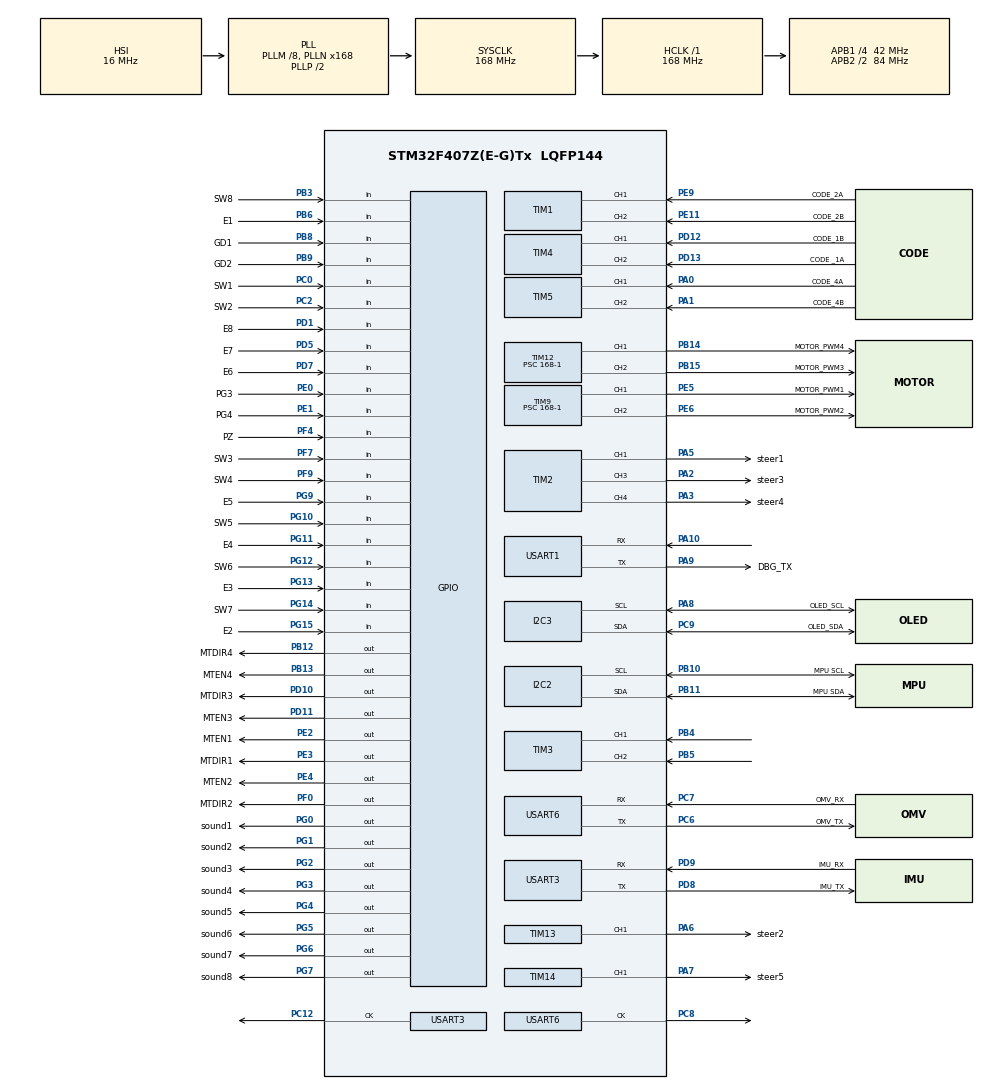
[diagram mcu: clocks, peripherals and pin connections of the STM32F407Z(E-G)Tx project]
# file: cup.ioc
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Mcu.Family=STM32F4
Mcu.Name=STM32F407Z(E-G)Tx
Mcu.Package=LQFP144
NVIC.PriorityGroup=NVIC_PRIORITYGROUP_4
NVIC.USART3_IRQn=true\:0\:0\:false\:false\:true\:true\:true\:true
PA0-WKUP.GPIO_Label=CODE_4A
PA0-WKUP.Signal=S_TIM5_CH1
PA1.GPIO_Label=CODE_4B
PA1.Signal=S_TIM5_CH2
PA10.Mode=Asynchronous
PA10.Signal=USART1_RX
PA13.Mode=Serial_Wire
PA13.Signal=SYS_JTMS-SWDIO
PA14.Mode=Serial_Wire
PA14.Signal=SYS_JTCK-SWCLK
PA2.GPIO_Label=steer3
PA2.Signal=S_TIM2_CH3
PA3.GPIO_Label=steer4
PA3.Signal=S_TIM2_CH4
PA5.GPIO_Label=steer1
PA5.Signal=S_TIM2_CH1_ETR
PA6.GPIO_Label=steer2
PA6.Signal=S_TIM13_CH1
PA7.GPIO_Label=steer5
PA7.Signal=S_TIM14_CH1
PA8.GPIO_Label=OLED_SCL
PA8.Mode=I2C
PA8.Signal=I2C3_SCL
PA9.GPIO_Label=DBG_TX
PA9.Mode=Asynchronous
PA9.Signal=USART1_TX
PB10.GPIO_Label=MPU SCL
PB10.Mode=I2C
PB10.Signal=I2C2_SCL
PB11.GPIO_Label=MPU SDA
PB11.Mode=I2C
PB11.Signal=I2C2_SDA
PB12.GPIO_Label=MTDIR4
PB12.Signal=GPIO_Output
PB13.GPIO_Label=MTEN4
PB13.Signal=GPIO_Output
PB14.GPIO_Label=MOTOR_PWM4
PB14.Signal=S_TIM12_CH1
PB15.GPIO_Label=MOTOR_PWM3
PB15.Signal=S_TIM12_CH2
PB3.GPIO_Label=SW8
PB3.Signal=GPIO_Input
PB4.Signal=S_TIM3_CH1
PB5.Signal=S_TIM3_CH2
PB6.GPIO_Label=E1
PB6.Signal=GPIO_Input
PB8.GPIO_Label=GD1
PB8.Signal=GPIO_Input
PB9.GPIO_Label=GD2
PB9.Signal=GPIO_Input
PC0.GPIO_Label=SW1
PC0.Signal=GPIO_Input
PC12.Mode=Synchronous
PC12.Signal=USART3_CK
PC14-OSC32_IN.Mode=LSE-External-Oscillator
PC14-OSC32_IN.Signal=RCC_OSC32_IN
PC15-OSC32_OUT.Mode=LSE-External-Oscillator
PC15-OSC32_OUT.Signal=RCC_OSC32_OUT
PC2.GPIO_Label=SW2
PC2.Signal=GPIO_Input
PC6.GPIO_Label=OMV_TX
PC6.Mode=Synchronous
PC6.Signal=USART6_TX
PC7.GPIO_Label=OMV_RX
PC7.Mode=Synchronous
PC7.Signal=USART6_RX
PC8.Mode=Synchronous
PC8.Signal=USART6_CK
PC9.GPIO_Label=OLED_SDA
PC9.Mode=I2C
PC9.Signal=I2C3_SDA
PD1.GPIO_Label=E8
PD1.Signal=GPIO_Input
PD10.GPIO_Label=MTDIR3
PD10.Signal=GPIO_Output
PD11.GPIO_Label=MTEN3
PD11.Signal=GPIO_Output
PD12.GPIO_Label=CODE_1B
PD12.Signal=S_TIM4_CH1
PD13.GPIO_Label=CODE _1A
PD13.Signal=S_TIM4_CH2
PD5.GPIO_Label=E7
PD5.Signal=GPIO_Input
PD7.GPIO_Label=E6
PD7.Signal=GPIO_Input
PD8.GPIO_Label=IMU_TX
PD8.Mode=Synchronous
PD8.Signal=USART3_TX
PD9.GPIO_Label=IMU_RX
PD9.Mode=Synchronous
PD9.Signal=USART3_RX
PE0.GPIO_Label=PG3
PE0.Signal=GPIO_Input
PE1.GPIO_Label=PG4
PE1.Signal=GPIO_Input
PE11.GPIO_Label=CODE_2B
PE11.Signal=S_TIM1_CH2
PE2.GPIO_Label=MTEN1
PE2.Signal=GPIO_Output
PE3.GPIO_Label=MTDIR1
PE3.Signal=GPIO_Output
PE4.GPIO_Label=MTEN2
PE4.Signal=GPIO_Output
PE5.GPIO_Label=MOTOR_PWM1
PE5.Signal=S_TIM9_CH1
PE6.GPIO_Label=MOTOR_PWM2
PE6.Signal=S_TIM9_CH2
PE9.GPIO_Label=CODE_2A
PE9.Signal=S_TIM1_CH1
PF0.GPIO_Label=MTDIR2
PF0.Signal=GPIO_Output
PF4.GPIO_Label=PZ
PF4.Signal=GPIO_Input
PF7.GPIO_Label=SW3
PF7.Signal=GPIO_Input
PF9.GPIO_Label=SW4
PF9.Signal=GPIO_Input
PG0.GPIO_Label=sound1
PG0.Signal=GPIO_Output
PG1.GPIO_Label=sound2
PG1.Signal=GPIO_Output
PG10.GPIO_Label=SW5
PG10.Signal=GPIO_Input
PG11.GPIO_Label=E4
PG11.Signal=GPIO_Input
PG12.GPIO_Label=SW6
PG12.Signal=GPIO_Input
PG13.GPIO_Label=E3
PG13.Signal=GPIO_Input
PG14.GPIO_Label=SW7
PG14.Signal=GPIO_Input
PG15.GPIO_Label=E2
PG15.Signal=GPIO_Input
PG2.GPIO_Label=sound3
PG2.Signal=GPIO_Output
PG3.GPIO_Label=sound4
PG3.Signal=GPIO_Output
PG4.GPIO_Label=sound5
PG4.Signal=GPIO_Output
PG5.GPIO_Label=sound6
PG5.Signal=GPIO_Output
PG6.GPIO_Label=sound7
PG6.Signal=GPIO_Output
PG7.GPIO_Label=sound8
PG7.Signal=GPIO_Output
PG9.GPIO_Label=E5
PG9.Signal=GPIO_Input
PH0-OSC_IN.Mode=HSE-External-Oscillator
PH0-OSC_IN.Signal=RCC_OSC_IN
PH1-OSC_OUT.Mode=HSE-External-Oscillator
PH1-OSC_OUT.Signal=RCC_OSC_OUT
ProjectManager.HeapSize=0x200
ProjectManager.StackSize=0x400
ProjectManager.TargetToolchain=MDK-ARM V5.32
RCC.48MHZClocksFreq_Value=84000000
RCC.AHBFreq_Value=168000000
RCC.APB1CLKDivider=RCC_HCLK_DIV4
RCC.APB1Freq_Value=42000000
RCC.APB1TimFreq_Value=84000000
RCC.APB2CLKDivider=RCC_HCLK_DIV2
RCC.APB2Freq_Value=84000000
RCC.APB2TimFreq_Value=168000000
RCC.CortexFreq_Value=168000000
RCC.HCLKFreq_Value=168000000
RCC.HSE_VALUE=25000000
RCC.HSI_VALUE=16000000
RCC.PLLM=8
RCC.PLLN=168
RCC.SYSCLKFreq_VALUE=168000000
RCC.SYSCLKSource=RCC_SYSCLKSOURCE_PLLCLK
RCC.VCOOutputFreq_Value=336000000
SH.S_TIM12_CH1.0=TIM12_CH1,PWM Generation1 CH1
SH.S_TIM12_CH2.0=TIM12_CH2,PWM Generation2 CH2
SH.S_TIM13_CH1.0=TIM13_CH1,PWM Generation1 CH1
SH.S_TIM14_CH1.0=TIM14_CH1,PWM Generation1 CH1
SH.S_TIM1_CH1.0=TIM1_CH1,Encoder_Interface
SH.S_TIM1_CH2.0=TIM1_CH2,Encoder_Interface
SH.S_TIM2_CH1_ETR.0=TIM2_CH1,PWM Generation1 CH1
SH.S_TIM2_CH3.0=TIM2_CH3,PWM Generation3 CH3
SH.S_TIM2_CH4.0=TIM2_CH4,PWM Generation4 CH4
SH.S_TIM3_CH1.0=TIM3_CH1,Encoder_Interface
SH.S_TIM3_CH2.0=TIM3_CH2,Encoder_Interface
SH.S_TIM4_CH1.0=TIM4_CH1,Encoder_Interface
SH.S_TIM4_CH2.0=TIM4_CH2,Encoder_Interface
SH.S_TIM5_CH1.0=TIM5_CH1,Encoder_Interface
SH.S_TIM5_CH2.0=TIM5_CH2,Encoder_Interface
SH.S_TIM9_CH1.0=TIM9_CH1,PWM Generation1 CH1
SH.S_TIM9_CH2.0=TIM9_CH2,PWM Generation2 CH2
TIM12.Channel-PWM\ Generation1\ CH1=TIM_CHANNEL_1
TIM12.Channel-PWM\ Generation2\ CH2=TIM_CHANNEL_2
TIM12.Period=1000
TIM12.Prescaler=168-1
TIM13.Channel=TIM_CHANNEL_1
TIM14.Channel=TIM_CHANNEL_1
TIM2.Channel-PWM\ Generation1\ CH1=TIM_CHANNEL_1
TIM2.Channel-PWM\ Generation3\ CH3=TIM_CHANNEL_3
TIM2.Channel-PWM\ Generation4\ CH4=TIM_CHANNEL_4
TIM9.Channel-PWM\ Generation1\ CH1=TIM_CHANNEL_1
TIM9.Channel-PWM\ Generation2\ CH2=TIM_CHANNEL_2
TIM9.Period=1000
TIM9.Prescaler=168-1
USART1.VirtualMode=VM_ASYNC
USART3.VirtualMode=VM_SYNC
USART6.VirtualMode=VM_SYNC
VP_TIM13_VS_ClockSourceINT.Mode=Enable_Timer
VP_TIM14_VS_ClockSourceINT.Mode=Enable_Timer
board=custom

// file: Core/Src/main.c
/* USER CODE BEGIN Header */
/**
  ******************************************************************************
  * @file           : main.c
  * @brief          : Main program body
  ******************************************************************************
  * @attention
  *
  * Copyright (c) 2024 STMicroelectronics.
  * All rights reserved.
  *
  * This software is licensed under terms that can be found in the LICENSE file
  * in the root directory of this software component.
  * If no LICENSE file comes with this software, it is provided AS-IS.
  *
  ******************************************************************************
  */
/* USER CODE END Header */
#include "main.h"
#include "i2c.h"
#include "tim.h"
#include "usart.h"
#include "gpio.h"

/* USER CODE BEGIN Includes */
#include "mpu.h"
#include "motor.h"
#include "chassis_task.h"
#include "gimbal_task.h"
#include "servo.h"
#include <stdint.h>
#include "pid.h"
#include "Grayscale_traces.h"
#include "chassis_task.h"
/* USER CODE END Includes */

/* USER CODE BEGIN PD */

extern GY_95_t myGY95;
flag_ST flag = {0,Disable,0,0,AD_Disable}; //��־λ�ṹ��:MPU--PID---timer1---adjust
extern int E1,E2,E3,E4,E5,E6,E7,E8,sum_E;
extern int flag_terrain;
//

/* USER CODE END PD */

void SystemClock_Config(void);

int main(void)
{

  /* MCU Configuration--------------------------------------------------------*/

  /* Reset of all peripherals, Initializes the Flash interface and the Systick. */
  HAL_Init();

  /* Configure the system clock */
  SystemClock_Config();

  /* Initialize all configured peripherals */
  MX_GPIO_Init();
  MX_I2C2_Init();
  MX_I2C3_Init();
  MX_TIM1_Init();
  MX_TIM2_Init();
  MX_TIM3_Init();
  MX_TIM4_Init();
  MX_TIM5_Init();
  MX_TIM9_Init();
  MX_TIM12_Init();
  MX_TIM13_Init();
  MX_TIM14_Init();
  MX_USART1_UART_Init();
  MX_USART3_Init();
  MX_USART6_Init();
  /* USER CODE BEGIN 2 */
	motor_init();
	//go_forward(600);
  servo_init();

	//motor_set_speed(500,500,500,500);

	//go_forward(700,Straight_Slow);
//	Grayscale_Read();
//		HAL_Delay(100);
//		if(sum_E >= 5)
//		{
//			go_forward(800,Straight_Quick);
//		}
//		else
//		{
//
//		}
  /* USER CODE END 2 */

  /* Infinite loop */
  /* USER CODE BEGIN WHILE */
  while (1)
  {

//		turn_left(250,250);
//		HAL_Delay(500);
//		stop();
//		HAL_Delay(1000);
//		turn_right(250,250);
//		HAL_Delay(500);
//		stop();
//		HAL_Delay(1000);
//		motor_set_speed(200,200,200,200);
//		HAL_Delay(500);
//		stop();
//		HAL_Delay(1000);

    /* USER CODE END WHILE */
		follow_white_line_1();
  }
}

void SystemClock_Config(void)
{
  RCC_OscInitTypeDef RCC_OscInitStruct = {0};
  RCC_ClkInitTypeDef RCC_ClkInitStruct = {0};

  /** Configure the main internal regulator output voltage
  */
  __HAL_RCC_PWR_CLK_ENABLE();
  __HAL_PWR_VOLTAGESCALING_CONFIG(PWR_REGULATOR_VOLTAGE_SCALE1);

  /** Initializes the RCC Oscillators according to the specified parameters
  * in the RCC_OscInitTypeDef structure.
  */
  RCC_OscInitStruct.OscillatorType = RCC_OSCILLATORTYPE_HSI;
  RCC_OscInitStruct.HSIState = RCC_HSI_ON;
  RCC_OscInitStruct.HSICalibrationValue = RCC_HSICALIBRATION_DEFAULT;
  RCC_OscInitStruct.PLL.PLLState = RCC_PLL_ON;
  RCC_OscInitStruct.PLL.PLLSource = RCC_PLLSOURCE_HSI;
  RCC_OscInitStruct.PLL.PLLM = 8;
  RCC_OscInitStruct.PLL.PLLN = 168;
  RCC_OscInitStruct.PLL.PLLP = RCC_PLLP_DIV2;
  RCC_OscInitStruct.PLL.PLLQ = 4;
  if (HAL_RCC_OscConfig(&RCC_OscInitStruct) != HAL_OK)
  {
    Error_Handler();
  }

  /** Initializes the CPU, AHB and APB buses clocks
  */
  RCC_ClkInitStruct.ClockType = RCC_CLOCKTYPE_HCLK|RCC_CLOCKTYPE_SYSCLK
                              |RCC_CLOCKTYPE_PCLK1|RCC_CLOCKTYPE_PCLK2;
  RCC_ClkInitStruct.SYSCLKSource = RCC_SYSCLKSOURCE_PLLCLK;
  RCC_ClkInitStruct.AHBCLKDivider = RCC_SYSCLK_DIV1;
  RCC_ClkInitStruct.APB1CLKDivider = RCC_HCLK_DIV4;
  RCC_ClkInitStruct.APB2CLKDivider = RCC_HCLK_DIV2;

  if (HAL_RCC_ClockConfig(&RCC_ClkInitStruct, FLASH_LATENCY_5) != HAL_OK)
  {
    Error_Handler();
  }
}

/* USER CODE BEGIN 4 */
uint16_t USART_ReceiveData(USART_TypeDef* USARTx)
{
  /* Check the parameters */
  assert_param(IS_USART_ALL_PERIPH(USARTx));

  /* Receive Data */
  return (uint16_t)(USARTx->DR & (uint16_t)0x01FF);
}
/* USER CODE END 4 */

void Error_Handler(void)
{
  __disable_irq();
  while (1)
  {
  }
}
